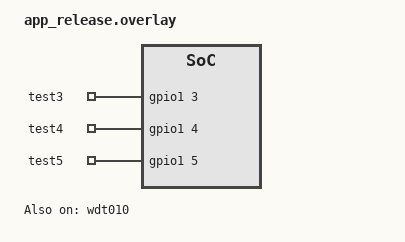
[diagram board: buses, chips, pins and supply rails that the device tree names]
/*
 * Copyright (c) 2024 Nordic Semiconductor ASA
 *
 * SPDX-License-Identifier: LicenseRef-Nordic-5-Clause
 */

#include "app_common.dtsi"

/ {
	hid_dev_0: hid_dev_0 {
		compatible = "zephyr,hid-device";
		interface-name = "HID0";
		protocol-code = "mouse";
		in-polling-period-us = <125>;
		in-report-size = <64>;
	};

	test_gpio {
		compatible = "gpio-keys";
		test3: test3 {
			gpios = <&gpio1 3 GPIO_ACTIVE_HIGH>;
		};
		test4: test4 {
			gpios = <&gpio1 4 GPIO_ACTIVE_HIGH>;
		};
		test5: test5 {
			gpios = <&gpio1 5 GPIO_ACTIVE_HIGH>;
		};
	};
};

/* For nRF54H, watchdog status is disabled by default. Needs to be enabled in DTS overlay. */
&wdt010 {
	status = "okay";
};

&gpio1 {
    status = "okay";
};
&gpiote130 {
    status = "okay";
};
